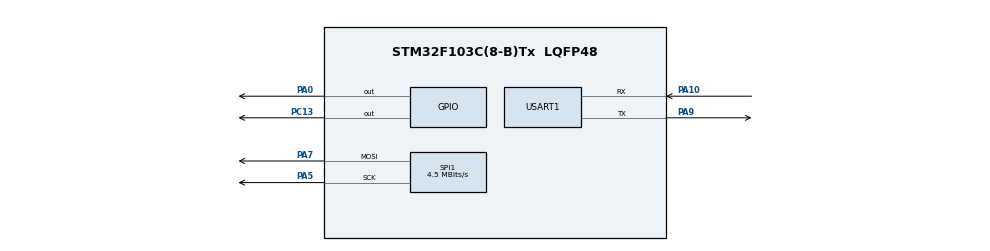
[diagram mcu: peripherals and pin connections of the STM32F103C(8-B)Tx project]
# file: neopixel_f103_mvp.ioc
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Dma.Request0=SPI1_TX
Dma.SPI1_TX.0.Direction=DMA_MEMORY_TO_PERIPH
Dma.SPI1_TX.0.Instance=DMA1_Channel3
Dma.SPI1_TX.0.MemDataAlignment=DMA_MDATAALIGN_BYTE
Dma.SPI1_TX.0.MemInc=DMA_MINC_ENABLE
Dma.SPI1_TX.0.Mode=DMA_CIRCULAR
Dma.SPI1_TX.0.PeriphDataAlignment=DMA_PDATAALIGN_BYTE
Dma.SPI1_TX.0.PeriphInc=DMA_PINC_DISABLE
Dma.SPI1_TX.0.Priority=DMA_PRIORITY_HIGH
FREERTOS.INCLUDE_xTaskGetCurrentTaskHandle=1
FREERTOS.Tasks01=AppTask,0,64,App,As weak,NULL,Static,defaultTaskBuffer,defaultTaskControlBlock
FREERTOS.configLIBRARY_MAX_SYSCALL_INTERRUPT_PRIORITY=1
FREERTOS.configMINIMAL_STACK_SIZE=64
FREERTOS.configTIMER_TASK_STACK_DEPTH=64
FREERTOS.configUSE_NEWLIB_REENTRANT=1
FREERTOS.configUSE_TIMERS=1
Mcu.Family=STM32F1
Mcu.Name=STM32F103C(8-B)Tx
Mcu.Package=LQFP48
NVIC.DMA1_Channel3_IRQn=true\:1\:0\:true\:false\:false\:false\:false\:false\:true
NVIC.PriorityGroup=NVIC_PRIORITYGROUP_4
PA0-WKUP.GPIO_Speed=GPIO_SPEED_FREQ_MEDIUM
PA0-WKUP.Signal=GPIO_Output
PA10.Mode=Asynchronous
PA10.Signal=USART1_RX
PA13.Mode=Serial_Wire
PA13.Signal=SYS_JTMS-SWDIO
PA14.Mode=Serial_Wire
PA14.Signal=SYS_JTCK-SWCLK
PA5.Mode=TX_Only_Simplex_Unidirect_Master
PA5.Signal=SPI1_SCK
PA7.Mode=TX_Only_Simplex_Unidirect_Master
PA7.Signal=SPI1_MOSI
PA9.Mode=Asynchronous
PA9.Signal=USART1_TX
PC13-TAMPER-RTC.GPIO_Speed=GPIO_SPEED_FREQ_MEDIUM
PC13-TAMPER-RTC.Signal=GPIO_Output
PC14-OSC32_IN.Mode=LSE-External-Oscillator
PC14-OSC32_IN.Signal=RCC_OSC32_IN
PC15-OSC32_OUT.Mode=LSE-External-Oscillator
PC15-OSC32_OUT.Signal=RCC_OSC32_OUT
PD0-OSC_IN.Mode=HSE-External-Oscillator
PD0-OSC_IN.Signal=RCC_OSC_IN
PD1-OSC_OUT.Mode=HSE-External-Oscillator
PD1-OSC_OUT.Signal=RCC_OSC_OUT
ProjectManager.HeapSize=0x200
ProjectManager.StackSize=0x400
ProjectManager.TargetToolchain=STM32CubeIDE
RCC.AHBFreq_Value=72000000
RCC.APB1CLKDivider=RCC_HCLK_DIV2
RCC.APB1Freq_Value=36000000
RCC.APB1TimFreq_Value=72000000
RCC.APB2Freq_Value=72000000
RCC.APB2TimFreq_Value=72000000
RCC.HCLKFreq_Value=72000000
RCC.PLLMUL=RCC_PLL_MUL9
RCC.PLLSourceVirtual=RCC_PLLSOURCE_HSE
RCC.SYSCLKFreq_VALUE=72000000
RCC.SYSCLKSource=RCC_SYSCLKSOURCE_PLLCLK
RCC.USBFreq_Value=72000000
SPI1.BaudRatePrescaler=SPI_BAUDRATEPRESCALER_16
SPI1.CalculateBaudRate=4.5 MBits/s
SPI1.Direction=SPI_DIRECTION_2LINES
SPI1.Mode=SPI_MODE_MASTER
SPI1.VirtualType=VM_MASTER
USART1.VirtualMode=VM_ASYNC
VP_FREERTOS_VS_CMSIS_V1.Mode=CMSIS_V1
board=custom

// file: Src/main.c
/* USER CODE BEGIN Header */
/**
  ******************************************************************************
  * @file           : main.c
  * @brief          : Main program body
  ******************************************************************************
  * @attention
  *
  * <h2><center>&copy; Copyright (c) 2020 STMicroelectronics.
  * All rights reserved.</center></h2>
  *
  * This software component is licensed by ST under BSD 3-Clause license,
  * the "License"; You may not use this file except in compliance with the
  * License. You may obtain a copy of the License at:
  *                        opensource.org/licenses/BSD-3-Clause
  *
  ******************************************************************************
  */
/* USER CODE END Header */
#include "main.h"
#include "cmsis_os.h"
#include "dma.h"
#include "spi.h"
#include "usart.h"
#include "gpio.h"

/* USER CODE BEGIN Includes */
#include <string.h>

/* USER CODE END Includes */

/* USER CODE BEGIN PV */
/* Private variables ---------------------------------------------------------*/

/* USER CODE END PV */

void SystemClock_Config(void);
void MX_FREERTOS_Init(void);
/* USER CODE BEGIN PFP */
/* Private function prototypes -----------------------------------------------*/
void App();
/* USER CODE END PFP */

int main(void)
{

  /* MCU Configuration--------------------------------------------------------*/

  /* Reset of all peripherals, Initializes the Flash interface and the Systick. */
  LL_APB2_GRP1_EnableClock(LL_APB2_GRP1_PERIPH_AFIO);
  LL_APB1_GRP1_EnableClock(LL_APB1_GRP1_PERIPH_PWR);

  /* System interrupt init*/
  NVIC_SetPriorityGrouping(NVIC_PRIORITYGROUP_4);

  /* PendSV_IRQn interrupt configuration */
  NVIC_SetPriority(PendSV_IRQn, NVIC_EncodePriority(NVIC_GetPriorityGrouping(),15, 0));
  /* SysTick_IRQn interrupt configuration */
  NVIC_SetPriority(SysTick_IRQn, NVIC_EncodePriority(NVIC_GetPriorityGrouping(),15, 0));

  /** NOJTAG: JTAG-DP Disabled and SW-DP Enabled
  */
  LL_GPIO_AF_Remap_SWJ_NOJTAG();

  /* Configure the system clock */
  SystemClock_Config();

  /* Initialize all configured peripherals */
  MX_GPIO_Init();
  MX_DMA_Init();
  MX_SPI1_Init();
  MX_USART1_UART_Init();
  /* USER CODE BEGIN 2 */

  LL_SYSTICK_EnableIT();

  /* USER CODE END 2 */

  /* Call init function for freertos objects (in cmsis_os2.c) */
  MX_FREERTOS_Init();

  /* Start scheduler */
  osKernelStart();

  /* We should never get here as control is now taken by the scheduler */

  /* Infinite loop */
  while(1) {

  }
}

void SystemClock_Config(void)
{
  LL_FLASH_SetLatency(LL_FLASH_LATENCY_2);
  while(LL_FLASH_GetLatency()!= LL_FLASH_LATENCY_2)
  {
  }
  LL_RCC_HSE_Enable();

   /* Wait till HSE is ready */
  while(LL_RCC_HSE_IsReady() != 1)
  {

  }
  LL_RCC_PLL_ConfigDomain_SYS(LL_RCC_PLLSOURCE_HSE_DIV_1, LL_RCC_PLL_MUL_9);
  LL_RCC_PLL_Enable();

   /* Wait till PLL is ready */
  while(LL_RCC_PLL_IsReady() != 1)
  {

  }
  LL_RCC_SetAHBPrescaler(LL_RCC_SYSCLK_DIV_1);
  LL_RCC_SetAPB1Prescaler(LL_RCC_APB1_DIV_2);
  LL_RCC_SetAPB2Prescaler(LL_RCC_APB2_DIV_1);
  LL_RCC_SetSysClkSource(LL_RCC_SYS_CLKSOURCE_PLL);

   /* Wait till System clock is ready */
  while(LL_RCC_GetSysClkSource() != LL_RCC_SYS_CLKSOURCE_STATUS_PLL)
  {

  }
  LL_Init1msTick(72000000);
  LL_SetSystemCoreClock(72000000);
}

void Error_Handler(void)
{
  while(1)
  {
  }
}

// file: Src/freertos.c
/* USER CODE BEGIN Header */
/**
  ******************************************************************************
  * File Name          : freertos.c
  * Description        : Code for freertos applications
  ******************************************************************************
  * @attention
  *
  * <h2><center>&copy; Copyright (c) 2020 STMicroelectronics.
  * All rights reserved.</center></h2>
  *
  * This software component is licensed by ST under Ultimate Liberty license
  * SLA0044, the "License"; You may not use this file except in compliance with
  * the License. You may obtain a copy of the License at:
  *                             www.st.com/SLA0044
  *
  ******************************************************************************
  */
/* USER CODE END Header */

#include "FreeRTOS.h"
#include "task.h"
#include "main.h"
#include "cmsis_os.h"

/* USER CODE BEGIN Includes */
#include "App/App.h"

/* USER CODE END Includes */

osThreadId AppTaskHandle;
uint32_t defaultTaskBuffer[ 64 ];
osStaticThreadDef_t defaultTaskControlBlock;

/* USER CODE BEGIN FunctionPrototypes */
#define __weak __WEAK

/* USER CODE END FunctionPrototypes */

void App(void const * argument);

void MX_FREERTOS_Init(void); /* (MISRA C 2004 rule 8.1) */

/* GetIdleTaskMemory prototype (linked to static allocation support) */
void vApplicationGetIdleTaskMemory( StaticTask_t **ppxIdleTaskTCBBuffer, StackType_t **ppxIdleTaskStackBuffer, uint32_t *pulIdleTaskStackSize );

/* GetTimerTaskMemory prototype (linked to static allocation support) */
void vApplicationGetTimerTaskMemory( StaticTask_t **ppxTimerTaskTCBBuffer, StackType_t **ppxTimerTaskStackBuffer, uint32_t *pulTimerTaskStackSize );

/* USER CODE BEGIN GET_IDLE_TASK_MEMORY */
static StaticTask_t xIdleTaskTCBBuffer;
static StackType_t xIdleStack[configMINIMAL_STACK_SIZE];

void vApplicationGetIdleTaskMemory( StaticTask_t **ppxIdleTaskTCBBuffer, StackType_t **ppxIdleTaskStackBuffer, uint32_t *pulIdleTaskStackSize )
{
  *ppxIdleTaskTCBBuffer = &xIdleTaskTCBBuffer;
  *ppxIdleTaskStackBuffer = &xIdleStack[0];
  *pulIdleTaskStackSize = configMINIMAL_STACK_SIZE;
  /* place for user code */
}
/* USER CODE END GET_IDLE_TASK_MEMORY */

/* USER CODE BEGIN GET_TIMER_TASK_MEMORY */
static StaticTask_t xTimerTaskTCBBuffer;
static StackType_t xTimerStack[configTIMER_TASK_STACK_DEPTH];

void vApplicationGetTimerTaskMemory( StaticTask_t **ppxTimerTaskTCBBuffer, StackType_t **ppxTimerTaskStackBuffer, uint32_t *pulTimerTaskStackSize )
{
  *ppxTimerTaskTCBBuffer = &xTimerTaskTCBBuffer;
  *ppxTimerTaskStackBuffer = &xTimerStack[0];
  *pulTimerTaskStackSize = configTIMER_TASK_STACK_DEPTH;
  /* place for user code */
}
/* USER CODE END GET_TIMER_TASK_MEMORY */

void MX_FREERTOS_Init(void) {

  /* Create the thread(s) */
  /* definition and creation of AppTask */
  osThreadStaticDef(AppTask, App, osPriorityNormal, 0, 64, defaultTaskBuffer, &defaultTaskControlBlock);
  AppTaskHandle = osThreadCreate(osThread(AppTask), NULL);

}

__weak void App(void const * argument)
{
  for(;;)
  {
    osDelay(1);
  }
}
